# STM32G544 register map
File version: 2.0.0
CPU: CM33 r0p4, little endian, MPU, FPU, 4 interrupt priority bits
Registers are 32-bit, read-write, reset 0x0 unless marked. A register's access mark holds for its fields unless they carry their own. Offsets are from the block's base; [hi:lo] are bit positions; {n}, {i} and the like mark numbered series.

## GTZC1_MPCBB2 — GTZC1_MPCBB2 register block
Base 0x40033000
Same registers: GTZC1_MPCBB2_S 0x50033000
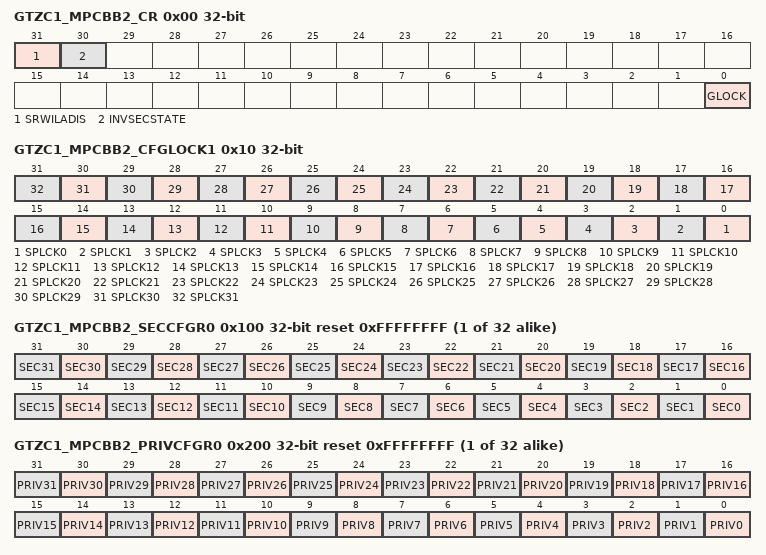
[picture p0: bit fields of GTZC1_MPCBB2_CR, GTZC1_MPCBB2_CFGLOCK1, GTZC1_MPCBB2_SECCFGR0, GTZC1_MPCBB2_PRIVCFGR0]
0x00 GTZC1_MPCBB2_CR — PLAYGTZC1 SRAM2 MPCBB control register
  [31] SRWILADIS — secure read/write illegal access disable
    0=enabled, secure read/write access not allowed on nonsecure SRAM block; 1=disabled, secure read/write access allowed on nonsecure SRAM block
  [30] INVSECSTATE — SRAMx clocks security state
    0=SRAMs clocks are secure if a secure area exists in the MPCBB; 1=SRAMs clocks are nonsecure even if a secure area exists in the MPCBB, and secure even if no secure block is set in the MPCBB
  [0] GLOCK — lock the control register of the MPCBB until next reset
    0=control register not locked; 1=control register locked
0x10 GTZC1_MPCBB2_CFGLOCK1 — GTZC1 SRAM2 MPCBB configuration lock register 1
  [all] fields
    0=GTZC1_MPCBBz_SECCFGRy and GTZC1_MPCBBz_PRIVCFGRy can be written; 1=Writes to GTZC1_MPCBBz_SECCFGRy and GTZC1_MPCBBz_PRIVCFGRy are ignored
  [n] SPLCK{n} (n=0..31) — Security/privilege configuration lock for super-block
{0x100+4i} GTZC1_MPCBB2_SECCFGR{i} reset 0xFFFFFFFF (i=0..31) — GTZC1 SRAM2 MPCBB security configuration for super-block {i} register
  [all] fields
    0=nonsecure access only to block y, belonging to super-block x; 1=Secure access only to block y, belonging to super-block x
  [n] SEC{n} (n=0..31) — Security configuration for block y
{0x200+4i} GTZC1_MPCBB2_PRIVCFGR{i} reset 0xFFFFFFFF (i=0..31) — GTZC1 SRAM2 MPCBB privileged configuration for super-block {i} register
  [all] fields
    0=Privileged and unprivileged access to block y, belonging to super-block x; 1=Only privileged access to block y, belonging to super-block x
  [n] PRIV{n} (n=0..31) — Privileged configuration for block y, belonging to super-block x (y = 31 to 0).

## GTZC1_MPCBB1 — GTZC1_MPCBB1 register block
Base 0x40032C00
Same registers: GTZC1_MPCBB1_S 0x50032C00
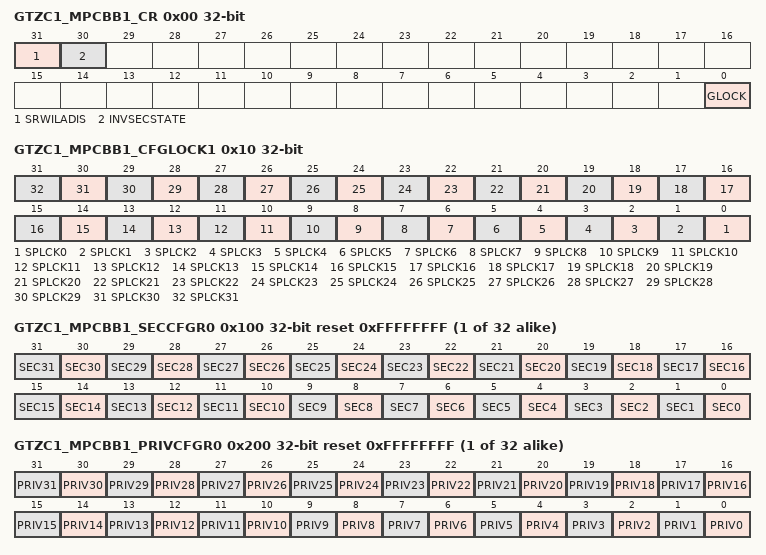
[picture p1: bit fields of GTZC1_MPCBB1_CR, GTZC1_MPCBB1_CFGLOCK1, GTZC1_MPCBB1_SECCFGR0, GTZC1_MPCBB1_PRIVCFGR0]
0x00 GTZC1_MPCBB1_CR — PLAYGTZC1 SRAM1 MPCBB control register
  [31] SRWILADIS — secure read/write illegal access disable
    0=enabled, secure read/write access not allowed on nonsecure SRAM block; 1=disabled, secure read/write access allowed on nonsecure SRAM block
  [30] INVSECSTATE — SRAMx clocks security state
    0=SRAMs clocks are secure if a secure area exists in the MPCBB; 1=SRAMs clocks are nonsecure even if a secure area exists in the MPCBB, and secure even if no secure block is set in the MPCBB
  [0] GLOCK — lock the control register of the MPCBB until next reset
    0=control register not locked; 1=control register locked
0x10 GTZC1_MPCBB1_CFGLOCK1 — GTZC1 SRAM1 MPCBB configuration lock register 1
  [all] fields
    0=GTZC1_MPCBBz_SECCFGRy and GTZC1_MPCBBz_PRIVCFGRy can be written; 1=Writes to GTZC1_MPCBBz_SECCFGRy and GTZC1_MPCBBz_PRIVCFGRy are ignored
  [n] SPLCK{n} (n=0..31) — Security/privilege configuration lock for super-block
{0x100+4i} GTZC1_MPCBB1_SECCFGR{i} reset 0xFFFFFFFF (i=0..31) — GTZC1 SRAM1 MPCBB security configuration for super-block {i} register
  [all] fields
    0=nonsecure access only to block y, belonging to super-block x; 1=Secure access only to block y, belonging to super-block x
  [n] SEC{n} (n=0..31) — Security configuration for block y
{0x200+4i} GTZC1_MPCBB1_PRIVCFGR{i} reset 0xFFFFFFFF (i=0..31) — GTZC1 SRAM1 MPCBB privileged configuration for super-block {i} register
  [all] fields
    0=Privileged and unprivileged access to block y, belonging to super-block x; 1=Only privileged access to block y, belonging to super-block x
  [n] PRIV{n} (n=0..31) — Privileged configuration for block y, belonging to super-block x (y = 31 to 0).

## HASH — HASH register bank
Base 0x46006400
Same registers: HASH_S 0x56006400
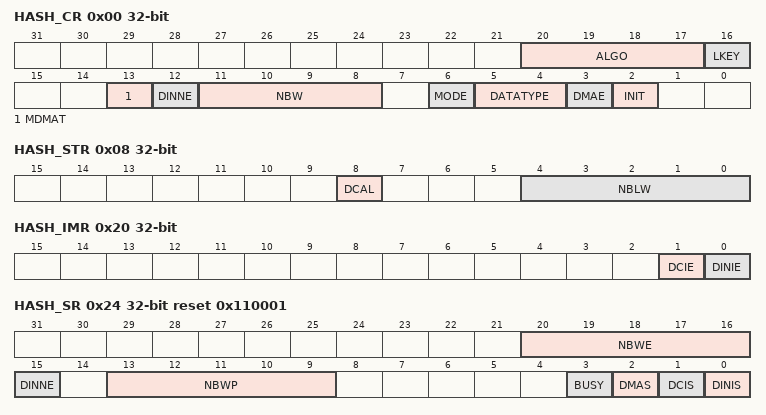
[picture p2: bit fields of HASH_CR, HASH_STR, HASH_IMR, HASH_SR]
0x00 HASH_CR — HASH control register
  [20:17] ALGO — Algorithm selection
    0=SHA-1; 2=SHA2-224; 3=SHA2-256; 12=SHA2-384; 13=SHA2-512/224; 14=SHA2-512/256; 15=SHA2-512
  [16] LKEY — Long key selection
    0=HMAC key is shorter or equal to the block size (short key); 1=HMAC key is longer than the block size (long key)
  [13] MDMAT — Multiple DMA transfers
    0=DCAL is automatically set at the end of a DMA transfer; 1=DCAL is not automatically set at the end of a DMA transfer
  [12] DINNE ro — DIN not empty
  [11:8] NBW ro — Number of words already pushed
  [6] MODE — Mode selection
    0=Hash mode selected; 1=HMAC mode selected
  [5:4] DATATYPE — Data type selection
    0=32-bit data; 1=16-bit data or half-word; 2=8-bit data or bytes; 3=bit data or bit string
  [3] DMAE — DMA enable
    0=DMA transfers disabled; 1=DMA transfers enabled
  [2] INIT — Initialize message digest calculation
0x04 HASH_DIN wo — HASH data input register
  [31:0] DATAIN — Data input
0x08 HASH_STR — HASH start register
  [8] DCAL — Digest calculation
  [4:0] NBLW — Number of valid bits in the last word
    0=All the 32 bits of the last data written are valid message bits, that is M[31:0]; 1=Only one bit of the last data written (after swapping) is valid, that is M[0]; 2=Only two bits of the last data written (after swapping) are valid, that is M[1:0]; 3=Only three bits of the last data written (after swapping) are valid that is M[2:0]; 31=Only 31 bits of the last data written (after swapping) are valid that is M[30:0]
{0xC+4i} HASH_HRA{i} ro (i=0..4) — HASH aliased digest register {i}
  [31:0] H{i} — Hash data x
0x20 HASH_IMR — HASH interrupt enable register
  [1] DCIE — Digest calculation completion interrupt enable
    0=Digest calculation completion interrupt disabled; 1=Digest calculation completion interrupt enabled
  [0] DINIE — Data input interrupt enable
    0=Data input interrupt disabled; 1=Data input interrupt enabled
0x24 HASH_SR reset 0x110001 — HASH status register
  [20:16] NBWE ro — Number of words expected
  [15] DINNE ro — DIN not empty
    0=No data are present in the data input buffer; 1=The input buffer contains at least one word of data
  [13:9] NBWP ro — Number of words already pushed
  [3] BUSY ro — Busy bit
    0=No block is currently being processed; 1=The hash core is processing a block of data
  [2] DMAS ro — DMA Status
    0=DMA interface is disabled (DMAE=0) and no transfer is ongoing; 1=DMA interface is enabled (DMAE=1) or a transfer is ongoing
  [1] DCIS — Digest calculation completion interrupt status
    0=No digest available in the HASH_HRx registers (zeros are returned); 1=Digest calculation complete, a digest is available in the HASH_HRx registers
  [0] DINIS — Data input interrupt status
    0=Less than 16 locations are free in the input buffer; 1=A new block can be entered into the input buffer
{0xF8+4i} HASH_CSR{i} (i=0..102) — HASH context swap register {i}
  [31:0] CS{i} — Context swap x
{0x310+4i} HASH_HR{i} ro (i=0..4) — HASH digest register {i}
  [31:0] H{i} — Hash data x
{0x310+4i} HASH_HR{i} ro (i=5..15) — HASH supplementary digest register {i}
  [31:0] H{i} — Hash data x
